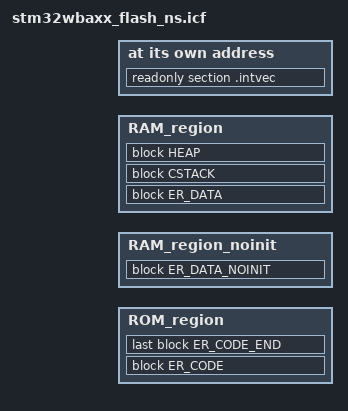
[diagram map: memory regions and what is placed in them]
/*###ICF### Section handled by ICF editor, don't touch! ****/
/*-Editor annotation file-*/
/* IcfEditorFile="$TOOLKIT_DIR$\config\ide\IcfEditor\cortex_v1_0.xml" */
/*-Specials-*/
/*************************************************************************************************/
#include "appli_region_defs.h"

/*************************************************************************************************/
define symbol __ICFEDIT_intvec_start__     = NS_CODE_START;
/*-Memory Regions-*/
define symbol __ICFEDIT_region_ROM_start__ = NS_CODE_START;
define symbol __ICFEDIT_region_ROM_end__   = (NS_CODE_START + NS_CODE_SIZE - 1);
define symbol __ICFEDIT_region_RAM_start__ = NS_RAM_START;
define symbol __ICFEDIT_region_RAM_end__   = (NS_RAM_START + NS_RAM_SIZE - 1);

/*-Sizes-*/
define symbol __ICFEDIT_size_cstack__      = NS_C_STACK_SIZE;
define symbol __ICFEDIT_size_heap__        = NS_HEAP_SIZE;
/**** End of ICF editor section. ###ICF###*/

define memory mem with size = 4G;

define region ROM_region =   mem:[from __ICFEDIT_region_ROM_start__ to __ICFEDIT_region_ROM_end__];
define region RAM_region_noinit = mem:[from __ICFEDIT_region_RAM_start__ size RAM_NS_NO_INIT_SIZE];
define region RAM_region  =  mem:[from (__ICFEDIT_region_RAM_start__ + RAM_NS_NO_INIT_SIZE) size (NS_RAM_SIZE - RAM_NS_NO_INIT_SIZE)];

define block CSTACK	with alignment = 8, size = __ICFEDIT_size_cstack__ { };
define block HEAP       with alignment = 8, size = __ICFEDIT_size_heap__ { };
define block ER_DATA_NOINIT { section .noinit};
define block ER_CODE		with alignment = 8 {readonly};
define block ER_CODE_END with alignment = 32, size = 0 { };

place at address mem:__ICFEDIT_intvec_start__ { readonly section .intvec };
define block ER_DATA with maximum size = 0x20000, alignment = 8 {readwrite};

do not initialize  { section .noinit };
initialize by copy with packing = none{ readwrite };


place in ROM_region  { block ER_CODE , last block ER_CODE_END,};
place in RAM_region_noinit  { block  ER_DATA_NOINIT };
place in RAM_region   { block ER_DATA, block CSTACK, block HEAP };
